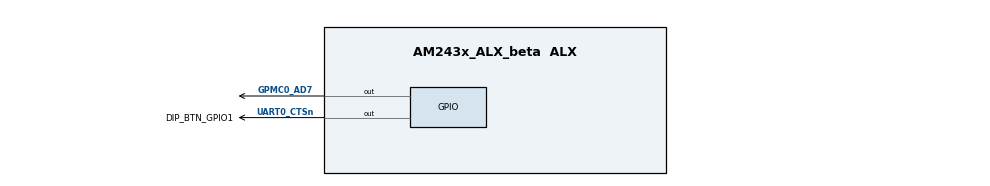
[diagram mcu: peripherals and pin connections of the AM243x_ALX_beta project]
/**
 * @cliArgs --device "AM243x_ALX_beta" --package "ALX" --part "ALX" --context "r5fss0-0" --product "INDUSTRIAL_COMMUNICATIONS_SDK_AM243X@09.02.00"
 * @versions {"tool":"1.20.0_3587"}
 */

/**
 * Import the modules used in this configuration.
 */
const eeprom          = scripting.addModule("/board/eeprom/eeprom", {}, false);
const eeprom1         = eeprom.addInstance();
const flash           = scripting.addModule("/board/flash/flash", {}, false);
const flash1          = flash.addInstance();
const led             = scripting.addModule("/board/led/led", {}, false);
const led1            = led.addInstance();
const gpio            = scripting.addModule("/drivers/gpio/gpio", {}, false);
const gpio1           = gpio.addInstance();
const gpio2           = gpio.addInstance();
const i2c             = scripting.addModule("/drivers/i2c/i2c", {}, false);
const i2c1            = i2c.addInstance();
const pruicss         = scripting.addModule("/drivers/pruicss/pruicss", {}, false);
const pruicss1        = pruicss.addInstance();
const uart            = scripting.addModule("/drivers/uart/uart", {}, false);
const uart1           = uart.addInstance();
const ethernetip      = scripting.addModule("/industrial_comms/ethernetip/ethernetip", {}, false);
const ethernetip1     = ethernetip.addInstance();
const clock           = scripting.addModule("/kernel/dpl/clock");
const debug_log       = scripting.addModule("/kernel/dpl/debug_log");
const mpu_armv7       = scripting.addModule("/kernel/dpl/mpu_armv7", {}, false);
const mpu_armv71      = mpu_armv7.addInstance();
const mpu_armv72      = mpu_armv7.addInstance();
const mpu_armv73      = mpu_armv7.addInstance();
const mpu_armv74      = mpu_armv7.addInstance();
const mpu_armv75      = mpu_armv7.addInstance();
const timer           = scripting.addModule("/kernel/dpl/timer", {}, false);
const timer1          = timer.addInstance();
const default_linker  = scripting.addModule("/memory_configurator/default_linker", {}, false);
const default_linker1 = default_linker.addInstance();
const general         = scripting.addModule("/memory_configurator/general", {}, false);
const general1        = general.addInstance();
const region          = scripting.addModule("/memory_configurator/region", {}, false);
const region1         = region.addInstance();
const section         = scripting.addModule("/memory_configurator/section", {}, false);
const section1        = section.addInstance();
const section2        = section.addInstance();
const section3        = section.addInstance();
const section4        = section.addInstance();
const section5        = section.addInstance();
const section6        = section.addInstance();
const section7        = section.addInstance();
const section8        = section.addInstance();
const section9        = section.addInstance();
const section10       = section.addInstance();
const section11       = section.addInstance();
const section12       = section.addInstance();
const section13       = section.addInstance();
const section14       = section.addInstance();

/**
 * Write custom configuration values to the imported modules.
 */
eeprom1.$name = "CONFIG_EEPROM0";

flash1.$name                         = "CONFIG_FLASH0";
flash1.flashQeType                   = "5";
flash1.peripheralDriver.$name        = "CONFIG_OSPI0";
flash1.peripheralDriver.OSPI.$assign = "OSPI0";

led1.$name = "CONFIG_LED0";
led1.name  = "TPIC2810";

gpio1.$name                = "CONFIG_GPIO0";
gpio1.GPIO.$assign         = "GPIO0";
gpio1.GPIO.gpioPin.$assign = "GPMC0_AD7";

gpio2.$name                = "DIP_BTN_GPIO1";
gpio2.GPIO.gpioPin.pu_pd   = "pd";
gpio2.GPIO.gpioPin.$assign = "UART0_CTSn";

i2c1.$name               = "CONFIG_I2C0";
led1.peripheralDriver    = i2c1;
eeprom1.peripheralDriver = i2c1;
i2c1.I2C.$assign         = "I2C0";

uart1.$name                   = "CONFIG_UART1";
uart1.intrEnable              = "USER_INTR";
uart1.rxTrigLvl               = "1";
uart1.useMcuDomainPeripherals = true;
uart1.MCU_UART.$assign        = "MCU_USART0";

ethernetip1.$name                                = "CONFIG_ETHERNETIP0";
ethernetip1.phyAddr1                             = 15;
ethernetip1.phyAddr0                             = 3;
ethernetip1.icss_emac[0].$name                   = "CONFIG_ICSS_EMAC0";
ethernetip1.icss_emac[0].mode                    = scripting.forceWrite("SWITCH");
ethernetip1.icss_emac[0].phyToMacInterfaceMode   = scripting.forceWrite("MII");
ethernetip1.icss_emac[0].learningEnable          = true;
ethernetip1.icss_emac[0].linkTaskPriority        = 24;
ethernetip1.icss_emac[0].rxTaskPriority          = 20;
ethernetip1.icss_emac[0].txTaskPriority          = 20;
ethernetip1.icss_emac[0].halfDuplexEnable        = true;
ethernetip1.ethphy1[0].$name                     = "CONFIG_ETHPHY0";
ethernetip1.ethphy1[0].mdioManualModeLinkPolling = scripting.forceWrite("Polling");
ethernetip1.ethphy1[0].name                      = "CUSTOM";
ethernetip1.ethphy1[0].customDeviceName          = "DP83869_0";
ethernetip1.ethphy2[0].$name                     = "CONFIG_ETHPHY1";
ethernetip1.ethphy2[0].mdioManualModeLinkPolling = scripting.forceWrite("Polling");
ethernetip1.ethphy2[0].name                      = "CUSTOM";
ethernetip1.ethphy2[0].customDeviceName          = "DP83869_1";

ethernetip1.icss                         = pruicss1;
pruicss1.$name                           = "CONFIG_PRU_ICSS1";
pruicss1.AdditionalICSSSettings[0].$name = "CONFIG_PRU_ICSS_IO0";

debug_log.enableUartLog        = true;
debug_log.uartLog.$name        = "CONFIG_UART_CONSOLE";
debug_log.uartLog.UART.$assign = "USART0";

const uart_v0_template  = scripting.addModule("/drivers/uart/v0/uart_v0_template", {}, false);
const uart_v0_template1 = uart_v0_template.addInstance({}, false);
uart_v0_template1.$name = "drivers_uart_v0_uart_v0_template0";
uart1.child             = uart_v0_template1;
debug_log.uartLog.child = uart_v0_template1;

mpu_armv71.$name        = "CONFIG_MPU_REGION0";
mpu_armv71.size         = 31;
mpu_armv71.attributes   = "Device";
mpu_armv71.allowExecute = false;

mpu_armv72.$name             = "CONFIG_MPU_REGION1";
mpu_armv72.size              = 15;
mpu_armv72.accessPermissions = "Supervisor RD+WR, User RD";

mpu_armv73.$name             = "CONFIG_MPU_REGION2";
mpu_armv73.baseAddr          = 0x41010000;
mpu_armv73.size              = 15;
mpu_armv73.accessPermissions = "Supervisor RD+WR, User RD";

mpu_armv74.$name             = "CONFIG_MPU_REGION3";
mpu_armv74.baseAddr          = 0x70000000;
mpu_armv74.size              = 21;
mpu_armv74.accessPermissions = "Supervisor RD+WR, User RD";

mpu_armv75.$name      = "CONFIG_MPU_REGION4";
mpu_armv75.size       = 16;
mpu_armv75.baseAddr   = 0x70000000;
mpu_armv75.attributes = "Cached+Sharable";

timer1.$name         = "CONFIG_TIMER0";
timer1.startTimer    = true;
timer1.timerCallback = "OSAL_FREERTOS_callbackTimer";
timer1.TIMER.$assign = "DMTIMER4";

default_linker1.$name = "memory_configurator_default_linker0";

general1.$name        = "CONFIG_GENERAL0";
general1.heap_size    = 131072;
general1.stack_size   = 1024;
general1.linker.$name = "TIARMCLANG0";

region1.$name                               = "MEMORY_REGION_CONFIGURATION0";
region1.memory_region.create(10);
region1.memory_region[0].type               = "TCMA_R5F";
region1.memory_region[0].$name              = "R5F_VECS";
region1.memory_region[0].size               = 0x40;
region1.memory_region[0].auto               = false;
region1.memory_region[1].type               = "TCMA_R5F";
region1.memory_region[1].$name              = "R5F_TCMA";
region1.memory_region[1].size               = 0x7FC0;
region1.memory_region[2].type               = "TCMB_R5F";
region1.memory_region[2].$name              = "R5F_TCMB0";
region1.memory_region[2].size               = 0x8000;
region1.memory_region[3].$name              = "NON_CACHE_MEM";
region1.memory_region[3].auto               = false;
region1.memory_region[3].manualStartAddress = 0x70060000;
region1.memory_region[3].size               = 0x8000;
region1.memory_region[4].$name              = "MSRAM";
region1.memory_region[4].auto               = false;
region1.memory_region[4].manualStartAddress = 0x70080000;
region1.memory_region[4].size               = 0x150000;
region1.memory_region[5].type               = "FLASH";
region1.memory_region[5].$name              = "FLASH";
region1.memory_region[5].auto               = false;
region1.memory_region[5].manualStartAddress = 0x60100000;
region1.memory_region[5].size               = 0x80000;
region1.memory_region[6].$name              = "USER_SHM_MEM";
region1.memory_region[6].auto               = false;
region1.memory_region[6].manualStartAddress = 0x701D0000;
region1.memory_region[6].isShared           = true;
region1.memory_region[6].shared_cores       = ["m4fss0-0","r5fss0-1","r5fss1-0","r5fss1-1"];
region1.memory_region[6].size               = 0x4000;
region1.memory_region[7].auto               = false;
region1.memory_region[7].$name              = "LOG_SHM_MEM";
region1.memory_region[7].isShared           = true;
region1.memory_region[7].shared_cores       = ["m4fss0-0","r5fss0-1","r5fss1-0","r5fss1-1"];
region1.memory_region[7].size               = 0x4000;
region1.memory_region[7].manualStartAddress = 0x701D4000;
region1.memory_region[8].auto               = false;
region1.memory_region[8].$name              = "RTOS_NORTOS_IPC_SHM_MEM";
region1.memory_region[8].manualStartAddress = 0x701D8000;
region1.memory_region[8].size               = 0x8000;
region1.memory_region[8].isShared           = true;
region1.memory_region[8].shared_cores       = ["m4fss0-0","r5fss0-1","r5fss1-0","r5fss1-1"];
region1.memory_region[9].$name              = "ICSS_PKT_BUF_MEM";
region1.memory_region[9].auto               = false;
region1.memory_region[9].size               = 0x10000;
region1.memory_region[9].isShared           = true;
region1.memory_region[9].shared_cores       = ["dmsc0-0","icss_g0_pru0","icss_g0_pru1","icss_g0_rtu_pru0","icss_g0_rtu_pru1","icss_g0_tx_pru0","icss_g0_tx_pru1","icss_g1_pru0","icss_g1_pru1","icss_g1_rtu_pru0","icss_g1_rtu_pru1","icss_g1_tx_pru0","icss_g1_tx_pru1","m4fss0-0","r5fss0-1","r5fss1-0","r5fss1-1"];

section1.$name                        = "Vector Table";
section1.load_memory                  = "R5F_VECS";
section1.group                        = false;
section1.output_section.create(1);
section1.output_section[0].$name      = ".vectors";
section1.output_section[0].palignment = true;

section2.$name                        = "Text Segments";
section2.load_memory                  = "R5F_TCMA";
section2.output_section.create(5);
section2.output_section[0].$name      = ".text.hwi";
section2.output_section[0].palignment = true;
section2.output_section[1].$name      = ".text.cache";
section2.output_section[1].palignment = true;
section2.output_section[2].$name      = ".text.mpu";
section2.output_section[2].palignment = true;
section2.output_section[3].$name      = ".text.boot";
section2.output_section[3].palignment = true;
section2.output_section[4].$name      = ".text:abort";
section2.output_section[4].palignment = true;

section3.load_memory                   = "MSRAM";
section3.$name                         = "Code";
section3.select_multiple_regions       = true;
section3.output_section.create(1);
section3.output_section[0].$name       = ".text";
section3.output_section[0].alignment   = 0;
section3.split_priority.create(3);
section3.split_priority[0].$name       = "Memory Region0";
section3.split_priority[0].load_memory = "R5F_TCMA";
section3.split_priority[1].$name       = "Memory Region1";
section3.split_priority[1].load_memory = "R5F_TCMB0";
section3.split_priority[2].$name       = "Memory Region2";
section3.split_priority[2].load_memory = "MSRAM";

section4.load_memory                  = "MSRAM";
section4.$name                        = "Read-Only Data and Data Segment";
section4.output_section.create(2);
section4.output_section[0].palignment = true;
section4.output_section[0].$name      = ".rodata";
section4.output_section[1].$name      = ".data";
section4.output_section[1].palignment = true;

section5.$name                                   = "Memory Segments";
section5.load_memory                             = "MSRAM";
section5.output_section.create(3);
section5.output_section[0].$name                 = ".bss";
section5.output_section[0].palignment            = true;
section5.output_section[0].output_sections_start = "__BSS_START";
section5.output_section[0].output_sections_end   = "__BSS_END";
section5.output_section[1].$name                 = ".sysmem";
section5.output_section[1].palignment            = true;
section5.output_section[1].output_sections_start = "__HEAP_START";
section5.output_section[1].output_sections_end   = "__HEAP_END";
section5.output_section[2].palignment            = true;
section5.output_section[2].$name                 = ".fbtlthreadstack";

section6.$name                                    = "Stack Segments";
section6.load_memory                              = "R5F_TCMA";
section6.output_section.create(5);
section6.output_section[0].$name                  = ".irqstack";
section6.output_section[0].output_sections_start  = "__IRQ_STACK_START";
section6.output_section[0].output_sections_end    = "__IRQ_STACK_END";
section6.output_section[0].input_section.create(1);
section6.output_section[0].input_section[0].$name = ". = . + __IRQ_STACK_SIZE;";
section6.output_section[1].$name                  = ".fiqstack";
section6.output_section[1].output_sections_start  = "__FIQ_STACK_START";
section6.output_section[1].output_sections_end    = "__FIQ_STACK_END";
section6.output_section[1].input_section.create(1);
section6.output_section[1].input_section[0].$name = ". = . + __FIQ_STACK_SIZE;";
section6.output_section[2].$name                  = ".svcstack";
section6.output_section[2].output_sections_start  = "__SVC_STACK_START";
section6.output_section[2].output_sections_end    = "__SVC_STACK_END";
section6.output_section[2].input_section.create(1);
section6.output_section[2].input_section[0].$name = ". = . + __SVC_STACK_SIZE;";
section6.output_section[3].$name                  = ".abortstack";
section6.output_section[3].output_sections_start  = "__ABORT_STACK_START";
section6.output_section[3].output_sections_end    = "__ABORT_STACK_END";
section6.output_section[3].input_section.create(1);
section6.output_section[3].input_section[0].$name = ". = . + __ABORT_STACK_SIZE;";
section6.output_section[4].$name                  = ".undefinedstack";
section6.output_section[4].output_sections_start  = "__UNDEFINED_STACK_START";
section6.output_section[4].output_sections_end    = "__UNDEFINED_STACK_END";
section6.output_section[4].input_section.create(1);
section6.output_section[4].input_section[0].$name = ". = . + __UNDEFINED_STACK_SIZE;";

section7.$name                        = "Initialization and Exception Handling";
section7.load_memory                  = "R5F_TCMA";
section7.output_section.create(3);
section7.output_section[0].$name      = ".ARM.exidx";
section7.output_section[0].palignment = true;
section7.output_section[1].$name      = ".init_array";
section7.output_section[1].palignment = true;
section7.output_section[2].$name      = ".fini_array";
section7.output_section[2].palignment = true;

section8.$name                       = "User Shared Memory";
section8.type                        = "NOLOAD";
section8.load_memory                 = "USER_SHM_MEM";
section8.group                       = false;
section8.output_section.create(1);
section8.output_section[0].$name     = ".bss.user_shared_mem";
section8.output_section[0].alignment = 0;

section9.$name                       = "Log Shared Memory";
section9.load_memory                 = "LOG_SHM_MEM";
section9.type                        = "NOLOAD";
section9.group                       = false;
section9.output_section.create(1);
section9.output_section[0].$name     = ".bss.log_shared_mem";
section9.output_section[0].alignment = 0;

section10.$name                       = "IPC Shared Memory";
section10.type                        = "NOLOAD";
section10.load_memory                 = "RTOS_NORTOS_IPC_SHM_MEM";
section10.group                       = false;
section10.output_section.create(1);
section10.output_section[0].$name     = ".bss.ipc_vring_mem";
section10.output_section[0].alignment = 0;

section11.$name                        = "TCMA Stack Segments";
section11.load_memory                  = "R5F_TCMA";
section11.output_section.create(1);
section11.output_section[0].$name      = ".stack";
section11.output_section[0].palignment = true;

section12.$name                        = "TCMB Stack Segments";
section12.load_memory                  = "R5F_TCMB0";
section12.output_section.create(1);
section12.output_section[0].palignment = true;
section12.output_section[0].$name      = ".threadstack";

section13.$name                        = "Packet Buffer Memory";
section13.type                         = "NOLOAD";
section13.group                        = false;
section13.load_memory                  = "ICSS_PKT_BUF_MEM";
section13.output_section.create(1);
section13.output_section[0].$name      = ".bss.icss_emac_pktbuf_mem";
section13.output_section[0].palignment = true;

section14.type                        = "NOLOAD";
section14.group                       = false;
section14.$name                       = "Non Cacheable Memory";
section14.load_memory                 = "NON_CACHE_MEM";
section14.output_section.create(1);
section14.output_section[0].$name     = ".bss.nocache";
section14.output_section[0].alignment = 0;

/**
 * Pinmux solution for unlocked pins/peripherals. This ensures that minor changes to the automatic solver in a future
 * version of the tool will not impact the pinmux you originally saw.  These lines can be completely deleted in order to
 * re-solve from scratch.
 */
flash1.peripheralDriver.OSPI.CLK.$suggestSolution            = "OSPI0_CLK";
flash1.peripheralDriver.OSPI.CSn0.$suggestSolution           = "OSPI0_CSn0";
flash1.peripheralDriver.OSPI.D3.$suggestSolution             = "OSPI0_D3";
flash1.peripheralDriver.OSPI.D2.$suggestSolution             = "OSPI0_D2";
flash1.peripheralDriver.OSPI.D1.$suggestSolution             = "OSPI0_D1";
flash1.peripheralDriver.OSPI.D0.$suggestSolution             = "OSPI0_D0";
gpio2.GPIO.$suggestSolution                                  = "GPIO1";
i2c1.I2C.SCL.$suggestSolution                                = "I2C0_SCL";
i2c1.I2C.SDA.$suggestSolution                                = "I2C0_SDA";
uart1.MCU_UART.RXD.$suggestSolution                          = "MCU_UART0_RXD";
uart1.MCU_UART.TXD.$suggestSolution                          = "MCU_UART0_TXD";
ethernetip1.PRU_ICSSG1_MDIO.$suggestSolution                 = "PRU_ICSSG1_MDIO0";
ethernetip1.PRU_ICSSG1_MDIO.MDC.$suggestSolution             = "PRG1_MDIO0_MDC";
ethernetip1.PRU_ICSSG1_MDIO.MDIO.$suggestSolution            = "PRG1_MDIO0_MDIO";
ethernetip1.PRU_ICSSG1_IEP.$suggestSolution                  = "PRU_ICSSG1_IEP0";
ethernetip1.PRU_ICSSG1_IEP.EDC_LATCH_IN0.$suggestSolution    = "PRG1_PRU0_GPO18";
ethernetip1.PRU_ICSSG1_IEP.EDC_SYNC_OUT0.$suggestSolution    = "PRG1_PRU0_GPO19";
ethernetip1.PRU_ICSSG1_MII_G_RT.$suggestSolution             = "PRU_ICSSG1_MII_G_RT";
ethernetip1.PRU_ICSSG1_MII_G_RT.MII0_RXD0.$suggestSolution   = "PRG1_PRU0_GPO0";
ethernetip1.PRU_ICSSG1_MII_G_RT.MII0_RXD1.$suggestSolution   = "PRG1_PRU0_GPO1";
ethernetip1.PRU_ICSSG1_MII_G_RT.MII0_RXD2.$suggestSolution   = "PRG1_PRU0_GPO2";
ethernetip1.PRU_ICSSG1_MII_G_RT.MII0_RXD3.$suggestSolution   = "PRG1_PRU0_GPO3";
ethernetip1.PRU_ICSSG1_MII_G_RT.MII0_RXDV.$suggestSolution   = "PRG1_PRU0_GPO4";
ethernetip1.PRU_ICSSG1_MII_G_RT.MII0_TXD0.$suggestSolution   = "PRG1_PRU0_GPO11";
ethernetip1.PRU_ICSSG1_MII_G_RT.MII0_TXD1.$suggestSolution   = "PRG1_PRU0_GPO12";
ethernetip1.PRU_ICSSG1_MII_G_RT.MII0_TXD2.$suggestSolution   = "PRG1_PRU0_GPO13";
ethernetip1.PRU_ICSSG1_MII_G_RT.MII0_TXD3.$suggestSolution   = "PRG1_PRU0_GPO14";
ethernetip1.PRU_ICSSG1_MII_G_RT.MII0_TXEN.$suggestSolution   = "PRG1_PRU0_GPO15";
ethernetip1.PRU_ICSSG1_MII_G_RT.MII1_RXD0.$suggestSolution   = "PRG1_PRU1_GPO0";
ethernetip1.PRU_ICSSG1_MII_G_RT.MII1_RXD1.$suggestSolution   = "PRG1_PRU1_GPO1";
ethernetip1.PRU_ICSSG1_MII_G_RT.MII1_RXD2.$suggestSolution   = "PRG1_PRU1_GPO2";
ethernetip1.PRU_ICSSG1_MII_G_RT.MII1_RXD3.$suggestSolution   = "PRG1_PRU1_GPO3";
ethernetip1.PRU_ICSSG1_MII_G_RT.MII1_RXDV.$suggestSolution   = "PRG1_PRU1_GPO4";
ethernetip1.PRU_ICSSG1_MII_G_RT.MII1_TXD0.$suggestSolution   = "PRG1_PRU1_GPO11";
ethernetip1.PRU_ICSSG1_MII_G_RT.MII1_TXD1.$suggestSolution   = "PRG1_PRU1_GPO12";
ethernetip1.PRU_ICSSG1_MII_G_RT.MII1_TXD2.$suggestSolution   = "PRG1_PRU1_GPO13";
ethernetip1.PRU_ICSSG1_MII_G_RT.MII1_TXD3.$suggestSolution   = "PRG1_PRU1_GPO14";
ethernetip1.PRU_ICSSG1_MII_G_RT.MII1_TXEN.$suggestSolution   = "PRG1_PRU1_GPO15";
ethernetip1.PRU_ICSSG1_MII_G_RT.MII_MR0_CLK.$suggestSolution = "PRG1_PRU0_GPO6";
ethernetip1.PRU_ICSSG1_MII_G_RT.MII_MR1_CLK.$suggestSolution = "PRG1_PRU1_GPO6";
ethernetip1.PRU_ICSSG1_MII_G_RT.MII_MT0_CLK.$suggestSolution = "PRG1_PRU0_GPO16";
ethernetip1.PRU_ICSSG1_MII_G_RT.MII_MT1_CLK.$suggestSolution = "PRG1_PRU1_GPO16";
debug_log.uartLog.UART.RXD.$suggestSolution                  = "UART0_RXD";
debug_log.uartLog.UART.TXD.$suggestSolution                  = "UART0_TXD";
